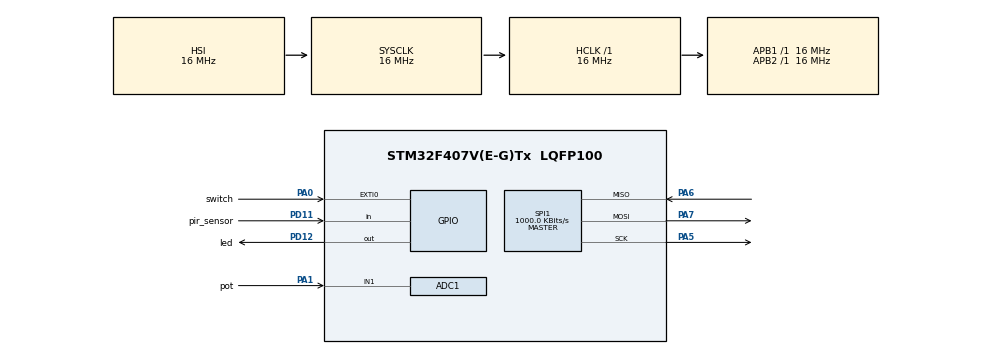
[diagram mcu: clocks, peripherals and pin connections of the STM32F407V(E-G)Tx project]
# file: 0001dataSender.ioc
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ADC1.Channel-0\#ChannelRegularConversion=ADC_CHANNEL_1
ADC1.NbrOfConversion=1
ADC1.NbrOfConversionFlag=1
ADC1.Rank-0\#ChannelRegularConversion=1
ADC1.Resolution=ADC_RESOLUTION_10B
ADC1.SamplingTime-0\#ChannelRegularConversion=ADC_SAMPLETIME_480CYCLES
ADC1.master=1
Mcu.Family=STM32F4
Mcu.Name=STM32F407V(E-G)Tx
Mcu.Package=LQFP100
NVIC.EXTI0_IRQn=true\:0\:0\:false\:false\:true\:true\:true
NVIC.PriorityGroup=NVIC_PRIORITYGROUP_4
PA0-WKUP.GPIO_Label=switch
PA0-WKUP.Signal=GPXTI0
PA1.GPIO_Label=pot
PA1.Signal=ADCx_IN1
PA13.Mode=Serial_Wire
PA13.Signal=SYS_JTMS-SWDIO
PA14.Mode=Serial_Wire
PA14.Signal=SYS_JTCK-SWCLK
PA5.Mode=Full_Duplex_Master
PA5.Signal=SPI1_SCK
PA6.Mode=Full_Duplex_Master
PA6.Signal=SPI1_MISO
PA7.Mode=Full_Duplex_Master
PA7.Signal=SPI1_MOSI
PD11.GPIO_Label=pir_sensor
PD11.Signal=GPIO_Input
PD12.GPIO_Label=led
PD12.Signal=GPIO_Output
PH0-OSC_IN.Mode=HSE-External-Oscillator
PH0-OSC_IN.Signal=RCC_OSC_IN
PH1-OSC_OUT.Mode=HSE-External-Oscillator
PH1-OSC_OUT.Signal=RCC_OSC_OUT
ProjectManager.HeapSize=0x200
ProjectManager.StackSize=0x400
ProjectManager.TargetToolchain=STM32CubeIDE
RCC.AHBFreq_Value=16000000
RCC.APB1Freq_Value=16000000
RCC.APB2Freq_Value=16000000
RCC.CortexFreq_Value=16000000
RCC.HSE_VALUE=25000000
RCC.HSI_VALUE=16000000
RCC.LSE_VALUE=32768
RCC.SYSCLKFreq_VALUE=16000000
RCC.VCOOutputFreq_Value=192000000
SH.ADCx_IN1.0=ADC1_IN1,IN1
SPI1.BaudRatePrescaler=SPI_BAUDRATEPRESCALER_16
SPI1.CalculateBaudRate=1000.0 KBits/s
SPI1.Direction=SPI_DIRECTION_2LINES
SPI1.Mode=SPI_MODE_MASTER
SPI1.VirtualType=VM_MASTER
board=custom

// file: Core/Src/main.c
/* USER CODE BEGIN Header */
/**
  ******************************************************************************
  * @file           : main.c
  * @brief          : Main program body
  ******************************************************************************
  * @attention
  *
  * <h2><center>&copy; Copyright (c) 2020 STMicroelectronics.
  * All rights reserved.</center></h2>
  *
  * This software component is licensed by ST under BSD 3-Clause license,
  * the "License"; You may not use this file except in compliance with the
  * License. You may obtain a copy of the License at:
  *                        opensource.org/licenses/BSD-3-Clause
  *
  ******************************************************************************
  */
/* USER CODE END Header */

#include "main.h"
#include<stdio.h>
/* USER CODE BEGIN Includes */
typedef struct
{
	uint8_t a;
	uint8_t g;
	uint8_t b;
	uint8_t c;
}data;
/* USER CODE END Includes */

ADC_HandleTypeDef hadc1;

SPI_HandleTypeDef hspi1;

void SystemClock_Config(void);
static void MX_GPIO_Init(void);
static void MX_SPI1_Init(void);
static void MX_ADC1_Init(void);

volatile uint8_t FLAG=0;
int main(void)
{
  /* USER CODE BEGIN 1 */
data d1;
  /* USER CODE END 1 */

  /* MCU Configuration--------------------------------------------------------*/
d1.a=0;
d1.g=1;
d1.b=2;
d1.c=3;
  /* Reset of all peripherals, Initializes the Flash interface and the Systick. */
  HAL_Init();

  /* Configure the system clock */
  SystemClock_Config();

  /* Initialize all configured peripherals */
  MX_GPIO_Init();
  MX_SPI1_Init();
  MX_ADC1_Init();

  /* Infinite loop */
  /* USER CODE BEGIN WHILE */

	  while (1)
	    {

	  	                HAL_Delay(1000);
	                       while(FLAG)
	                       {
	                    	   printf("the system is turned on");
	                      	 HAL_Delay(1000);
	                      	 HAL_GPIO_TogglePin(led_GPIO_Port, led_Pin);
	                      	 if(pot()>512)
	                      	 {
	                      		 if(pir()==1)
	                      		 {
	                      			 HAL_SPI_Transmit(&hspi1, &d1.b, 1, 100);
	                      			 printf("traces of human found");
	                      			 HAL_Delay(1000);
	                      		 }
	                      		 else if(pir()==0)
	                      		 {
	                      			 HAL_SPI_Transmit(&hspi1, &d1.c, 1, 100);
	                      			 printf("no traces of human");
	                      			 HAL_Delay(1000);
	                      		 }
	                      	 }
	                      	 else
	                      	 {
	                      		 HAL_SPI_Transmit(&hspi1, &d1.g, 1, 100);
	                      		 printf("pot value is less than 512");
	                      	 }
	                       }

	  		 			  HAL_Delay(1000);
	  		 			  HAL_SPI_Transmit(&hspi1, &d1.a, 1, 100);
	  		 			  printf("the system is turned off");
	  		 			  FLAG=0;
	  	  }
	    /* USER CODE END 3 */
	  }
  /* USER CODE END 3 */
void HAL_GPIO_EXTI_Callback(uint16_t GPIO_Pin)
{
	FLAG ^=1;
}
void SystemClock_Config(void)
{
  RCC_OscInitTypeDef RCC_OscInitStruct = {0};
  RCC_ClkInitTypeDef RCC_ClkInitStruct = {0};

  /** Configure the main internal regulator output voltage
  */
  __HAL_RCC_PWR_CLK_ENABLE();
  __HAL_PWR_VOLTAGESCALING_CONFIG(PWR_REGULATOR_VOLTAGE_SCALE1);
  /** Initializes the CPU, AHB and APB busses clocks
  */
  RCC_OscInitStruct.OscillatorType = RCC_OSCILLATORTYPE_HSI;
  RCC_OscInitStruct.HSIState = RCC_HSI_ON;
  RCC_OscInitStruct.HSICalibrationValue = RCC_HSICALIBRATION_DEFAULT;
  RCC_OscInitStruct.PLL.PLLState = RCC_PLL_NONE;
  if (HAL_RCC_OscConfig(&RCC_OscInitStruct) != HAL_OK)
  {
    Error_Handler();
  }
  /** Initializes the CPU, AHB and APB busses clocks
  */
  RCC_ClkInitStruct.ClockType = RCC_CLOCKTYPE_HCLK|RCC_CLOCKTYPE_SYSCLK
                              |RCC_CLOCKTYPE_PCLK1|RCC_CLOCKTYPE_PCLK2;
  RCC_ClkInitStruct.SYSCLKSource = RCC_SYSCLKSOURCE_HSI;
  RCC_ClkInitStruct.AHBCLKDivider = RCC_SYSCLK_DIV1;
  RCC_ClkInitStruct.APB1CLKDivider = RCC_HCLK_DIV1;
  RCC_ClkInitStruct.APB2CLKDivider = RCC_HCLK_DIV1;

  if (HAL_RCC_ClockConfig(&RCC_ClkInitStruct, FLASH_LATENCY_0) != HAL_OK)
  {
    Error_Handler();
  }
}

static void MX_ADC1_Init(void)
{

  ADC_ChannelConfTypeDef sConfig = {0};

  /** Configure the global features of the ADC (Clock, Resolution, Data Alignment and number of conversion)
  */
  hadc1.Instance = ADC1;
  hadc1.Init.ClockPrescaler = ADC_CLOCK_SYNC_PCLK_DIV2;
  hadc1.Init.Resolution = ADC_RESOLUTION_10B;
  hadc1.Init.ScanConvMode = DISABLE;
  hadc1.Init.ContinuousConvMode = DISABLE;
  hadc1.Init.DiscontinuousConvMode = DISABLE;
  hadc1.Init.ExternalTrigConvEdge = ADC_EXTERNALTRIGCONVEDGE_NONE;
  hadc1.Init.ExternalTrigConv = ADC_SOFTWARE_START;
  hadc1.Init.DataAlign = ADC_DATAALIGN_RIGHT;
  hadc1.Init.NbrOfConversion = 1;
  hadc1.Init.DMAContinuousRequests = DISABLE;
  hadc1.Init.EOCSelection = ADC_EOC_SINGLE_CONV;
  if (HAL_ADC_Init(&hadc1) != HAL_OK)
  {
    Error_Handler();
  }
  /** Configure for the selected ADC regular channel its corresponding rank in the sequencer and its sample time.
  */
  sConfig.Channel = ADC_CHANNEL_1;
  sConfig.Rank = 1;
  sConfig.SamplingTime = ADC_SAMPLETIME_480CYCLES;
  if (HAL_ADC_ConfigChannel(&hadc1, &sConfig) != HAL_OK)
  {
    Error_Handler();
  }

}

static void MX_SPI1_Init(void)
{

  /* SPI1 parameter configuration*/
  hspi1.Instance = SPI1;
  hspi1.Init.Mode = SPI_MODE_MASTER;
  hspi1.Init.Direction = SPI_DIRECTION_2LINES;
  hspi1.Init.DataSize = SPI_DATASIZE_8BIT;
  hspi1.Init.CLKPolarity = SPI_POLARITY_LOW;
  hspi1.Init.CLKPhase = SPI_PHASE_1EDGE;
  hspi1.Init.NSS = SPI_NSS_SOFT;
  hspi1.Init.BaudRatePrescaler = SPI_BAUDRATEPRESCALER_16;
  hspi1.Init.FirstBit = SPI_FIRSTBIT_MSB;
  hspi1.Init.TIMode = SPI_TIMODE_DISABLE;
  hspi1.Init.CRCCalculation = SPI_CRCCALCULATION_DISABLE;
  hspi1.Init.CRCPolynomial = 10;
  if (HAL_SPI_Init(&hspi1) != HAL_OK)
  {
    Error_Handler();
  }

}

static void MX_GPIO_Init(void)
{
  GPIO_InitTypeDef GPIO_InitStruct = {0};

  /* GPIO Ports Clock Enable */
  __HAL_RCC_GPIOH_CLK_ENABLE();
  __HAL_RCC_GPIOA_CLK_ENABLE();
  __HAL_RCC_GPIOD_CLK_ENABLE();

  /*Configure GPIO pin Output Level */
  HAL_GPIO_WritePin(led_GPIO_Port, led_Pin, GPIO_PIN_RESET);

  /*Configure GPIO pin : switch_Pin */
  GPIO_InitStruct.Pin = switch_Pin;
  GPIO_InitStruct.Mode = GPIO_MODE_IT_RISING;
  GPIO_InitStruct.Pull = GPIO_NOPULL;
  HAL_GPIO_Init(switch_GPIO_Port, &GPIO_InitStruct);

  /*Configure GPIO pin : pir_sensor_Pin */
  GPIO_InitStruct.Pin = pir_sensor_Pin;
  GPIO_InitStruct.Mode = GPIO_MODE_INPUT;
  GPIO_InitStruct.Pull = GPIO_NOPULL;
  HAL_GPIO_Init(pir_sensor_GPIO_Port, &GPIO_InitStruct);

  /*Configure GPIO pin : led_Pin */
  GPIO_InitStruct.Pin = led_Pin;
  GPIO_InitStruct.Mode = GPIO_MODE_OUTPUT_PP;
  GPIO_InitStruct.Pull = GPIO_NOPULL;
  GPIO_InitStruct.Speed = GPIO_SPEED_FREQ_LOW;
  HAL_GPIO_Init(led_GPIO_Port, &GPIO_InitStruct);

  /* EXTI interrupt init*/
  HAL_NVIC_SetPriority(EXTI0_IRQn, 0, 0);
  HAL_NVIC_EnableIRQ(EXTI0_IRQn);

}

void Error_Handler(void)
{
}

/************************ (C) COPYRIGHT STMicroelectronics *****END OF FILE****/
